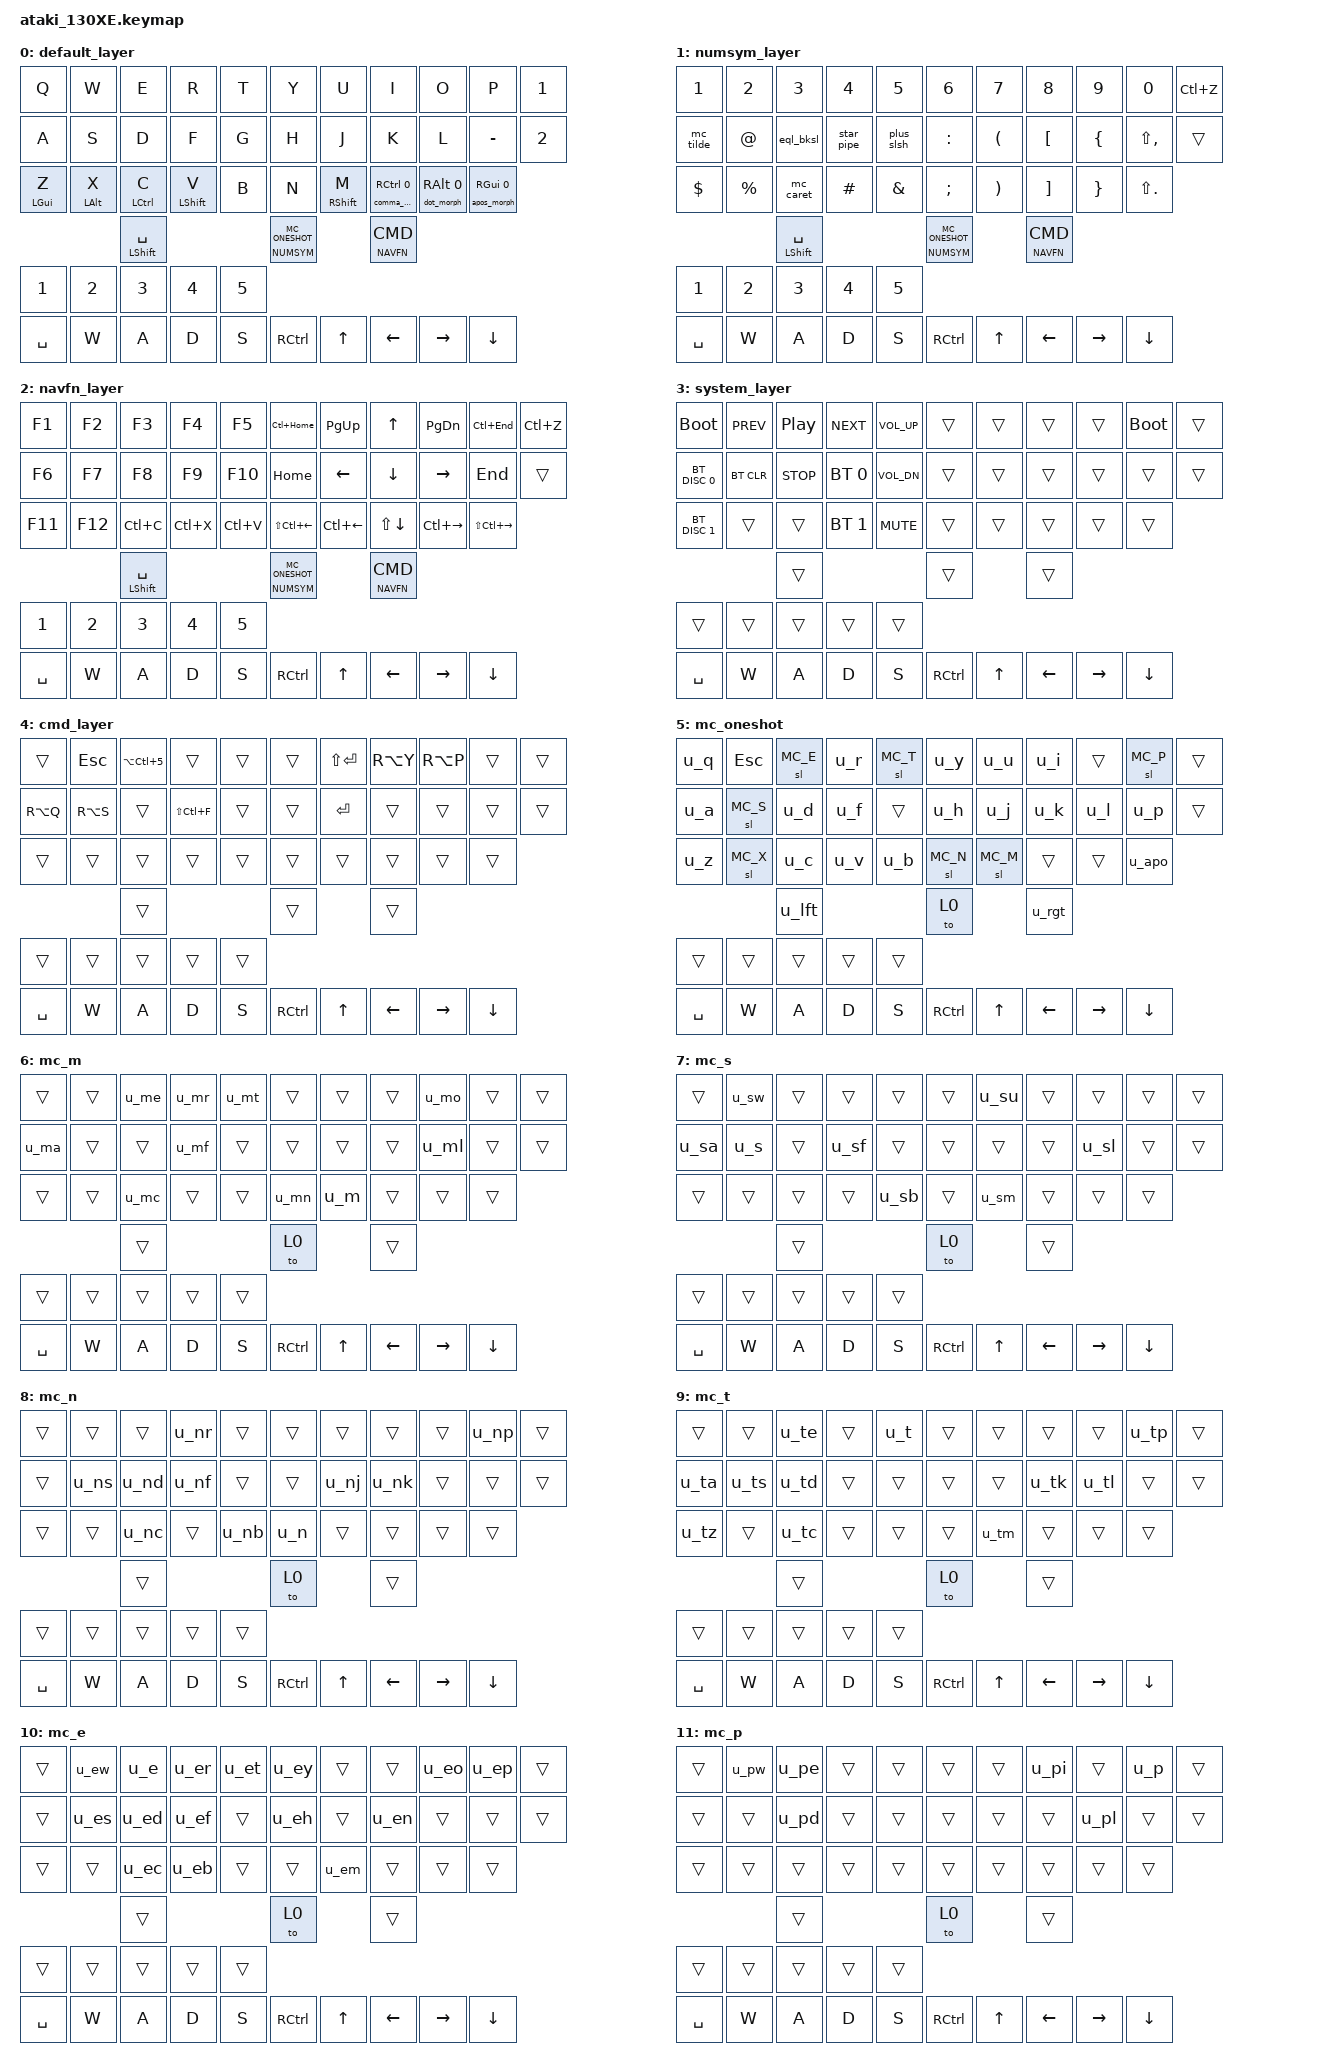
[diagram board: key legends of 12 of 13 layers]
#include <behaviors.dtsi>
#include <dt-bindings/zmk/keys.h>
#include <dt-bindings/zmk/bt.h>
#include "../../../inc/helpers.h"

// Layers
#define BASE 0
#define NUMSYM 1
#define NAVFN 2
#define SYSTEM 3
#define CMD 4
#define BASE_LAYERS BASE

#define MC_ONESHOT 5
#define MC_M       6
#define MC_S       7
#define MC_N       8
#define MC_T       9
#define MC_E       10
#define MC_P       11
#define MC_X       12

#define toM &sl MC_M
#define toS &sl MC_S
#define toN &sl MC_N
#define toT &sl MC_T
#define toE &sl MC_E
#define toP &sl MC_P
#define toX &sl MC_X

#define ___ &trans

/* How quickly Combo keys must be pressed together */
#define COMBO_TIMEOUT_MS 30
/* Macro timers; can be increased for systems that don't like 0ms Macros */
#define FAST_MACRO_TAP_MS 0
#define FAST_MACRO_WAIT_MS 0

/* Custom base layer punctuation */
SHIFT_MORPH(comma_qust, &kp COMMA, &kp QMARK)
SHIFT_MORPH(dot_exc, &kp DOT, &kp EXCL)
SHIFT_MORPH(eql_bksl, &kp EQUAL, &kp BSLH)
SHIFT_MORPH(star_pipe, &kp STAR, &kp PIPE)
SHIFT_MORPH(plus_slsh, &kp PLUS, &kp FSLH)

MY_HOLD_TAP(dot_morph, &dot_exc, &kp)
MY_HOLD_TAP(comma_morph, &comma_qust, &kp)
MY_HOLD_TAP(apos_morph, &mc_apos, &kp)

/ {
    behaviors {
       ht: hold_tap {
            compatible = "zmk,behavior-hold-tap";
            #binding-cells = <2>;
            flavor = "balanced";
            tapping-term-ms = <300>;
            require-prior-idle-ms = <100>;
            bindings = <&kp>, <&kp>;
        };

        /* Let Caps Word continue when typing Underscore */
        caps_word {
            continue-list = <UNDERSCORE MINUS BACKSPACE DELETE>;
        };

        hm: hold_mod {
            compatible = "zmk,behavior-hold-tap";
            #binding-cells = <2>;
            flavor = "balanced";
            tapping-term-ms = <300>;
            bindings = <&mo>, <&sl>;
        };
    };
    
    conditional_layers {
        compatible = "zmk,conditional-layers";
        tri_layer {
            if-layers = <NUMSYM NAVFN>;
            then-layer = <SYSTEM>;
        };
    };

#include "inc/leader_macros.h" 
#include "inc/combos.h" 
    
 // cheat-sheet for indexes
 //                   ───────────────
 //                  /35/36/37/38/39/
 // ┌───┬──┬──┬──┬──┬──┬──┬──┬──┬──┬────┐ ┌────────┐ ┌────────┐
 // │0  │1 │2 │3 │4 │5 │6 │7 │8 │9 │ 10 │ │      40│ │      45│
 // ├───┴┬─┴┬─┴┬─┴┬─┴┬─┴┬─┴┬─┴┬─┴┬─┴┬───┤ │   41   │ │   46   │
 // │11  │12│13│14│15│16│17│18│19│20│21 │ │42    43│ │47    48│
 // ├────┴─┬┴─┬┴─┬┴─┬┴─┬┴─┬┴─┬┴─┬┴──┴┬──┤ │   44   │ │   49   │
 // │22    │23│24│25│26│27│28│29│ 30 │31│ └────────┘ └────────┘
 // └─────┬┴──┴──┴──┴┬─┴┬─┴──┴──┴─┬──┴──┘  joystick1  joystick2
 //       │     32   │33│    34   │
 //       └──────────┴──┴─────────┘
/*
 * combos (see inc/combos.h for implementation)
 *                                  ───────────────────────────────────
 *                                 /      /      /      /      /      /
 *                                /      /      /      /      /      /
 * ┌──────┬─────┬─────┬─────┬─────┬─────┬─────┬─────┬─────┬─────┬──────────┐ ┌───────────┐ ┌───────────┐
 * │      │ +=Del=+=SftTab+ │     │     │     │ +=Del=+   │     │          │ │       ___ │ │       ___ │
 * │      │     │     │     │     │     │     │     │     │     │          │ │      /Spc\│ │      /Ctl\│
 * ├──────┴┬────┴┬────┴┬────┴┬────┴┬────┴┬────┴┬────┴┬────┴┬────┴┬─────────┤ │     W\___/│ │     ↑\___/│
 * │       │ +=BkSp=+=Tab=+  │     │     │     │  +=BkSp=+ │     │         │ │   ┌───┐   │ │   ┌───┐   │
 * │       │     │     │     │     │     │     │     │     │     │         │ │ A │J 1│ D │ │ ← │J 2│ → │
 * ├───────┴─┬───┴─┬───┴─┬───┴─┬───┴─┬───┴─┬───┴─┬───┴─┬───┴─┬───┴───┬─────┤ │   └───┘   │ │   └───┘   │
 * │    +=CtrlX+=CtrlC+CtrlV=+ │     │     │     │     │     │       │     │ │     S     │ │     ↓     │
 * │         │     │     │     │     │     │     │     │     │       │     │ └───────────┘ └───────────┘
 * └─────────┴┬────┴─────┴─────┴─┬───┴─┬───┴─────┴─────┴──┬──┴───────┴─────┘
 *            │                  │+=system==+             │
 *            │                  │     │                  │
 *            └──────────────────┴─────┴──────────────────┘
 */
    keymap {
        compatible = "zmk,keymap";
/*
 *                                  ───────────────────────────────────
 *                                 /      /      /      /      /      /
 *                                /      /      /      /      /      /
 * ┌──────┬─────┬─────┬─────┬─────┬─────┬─────┬─────┬─────┬─────┬──────────┐
 * │q     │w    │e    │r    │t    │y    │u    │i    │o    │p    │CtrlZ     │
 * │      │     │     │     │     │     │     │     │     │     │          │
 * ├──────┴┬────┴┬────┴┬────┴┬────┴┬────┴┬────┴┬────┴┬────┴┬────┴┬─────────┤
 * │a      │s    │d    │f    │g    │h    │j    │k    │l    │- _  │         │
 * │       │     │     │     │     │     │     │     │     │     │         │
 * ├───────┴─┬───┴─┬───┴─┬───┴─┬───┴─┬───┴─┬───┴─┬───┴─┬───┴─┬───┴───┬─────┤
 * │z        │x    │c    │v    │b    │n    │m    │, ?  │. !  │' "    │     │
 * │lgui     │lalt │lctl │lshft│     │     │rshft│rctl │ralt │rgui   │     │
 * └─────────┴┬────┴─────┴─────┴─┬───┴─┬───┴─────┴─────┴──┬──┴───────┴─────┘
 *            │      space       │lead │        cmd       │
 *            │      shift       │numsy│        navfn     │
 *            └──────────────────┴─────┴──────────────────┘
 */
        default_layer {
            bindings = <
            &kp Q      &kp W      &kp E      &kp R           &kp T           &kp Y                 &kp U         &kp I               &kp O             &kp P              &kp N1
            &kp A      &kp S      &kp D      &kp F           &kp G           &kp H                 &kp J         &kp K               &kp L             &kp MINUS          &kp N2
            &ht LGUI Z &ht LALT X &ht LCTL C &ht LSHFT V     &kp B           &kp N                 &ht RSHFT M   &comma_morph RCTL 0 &dot_morph RALT 0 &apos_morph RGUI 0
                                     &mt LSHFT SPACE                     &hm NUMSYM MC_ONESHOT                   &hm NAVFN CMD
            &kp N1  &kp N2  &kp N3  &kp N4  &kp N5
            &kp SPACE &kp W &kp A &kp D &kp S           &kp RCTL &kp UP &kp LEFT &kp RIGHT &kp DOWN
            >;
        };

/*
 *                                  ───────────────────────────────────
 *                                 /      /      /      /      /      /
 *                                /      /      /      /      /      /
 * ┌──────┬─────┬─────┬─────┬─────┬─────┬─────┬─────┬─────┬─────┬──────────┐
 * │1     │2    │3    │4    │5    │6    │7    │8    │9    │0    │CtrlZ     │
 * │      │     │     │     │     │     │     │     │     │     │          │
 * ├──────┴┬────┴┬────┴┬────┴┬────┴┬────┴┬────┴┬────┴┬────┴┬────┴┬─────────┤
 * │~      │@    │= \  │* |  │+ /  │:    │(    │[    │{    │<    │         │
 * │       │     │     │     │     │     │     │     │     │     │         │
 * ├───────┴─┬───┴─┬───┴─┬───┴─┬───┴─┬───┴─┬───┴─┬───┴─┬───┴─┬───┴───┬─────┤
 * │$        │%    │^    │#    │&    │;    │)    │] ,  │} .  │>      │     │
 * │         │     │     │     │     │     │     │     │     │       │     │
 * └─────────┴┬────┴─────┴─────┴─┬───┴─┬───┴─────┴─────┴──┬──┴───────┴─────┘
 *            │      space       │lead │        cmd       │
 *            │      shift       │numsy│        navfn     │
 *            └──────────────────┴─────┴──────────────────┘
 */
        numsym_layer {
            bindings = <
            &kp N1     &kp N2    &kp N3    &kp N4          &kp N5          &kp N6                &kp N7        &kp N8        &kp N9   &kp N0        &kp LC(Z)
            &mc_tilde  &kp AT    &eql_bksl &star_pipe      &plus_slsh      &kp COLON             &kp LPAR      &kp LBKT      &kp LBRC &kp LS(COMMA) ___    
            &kp DOLLAR &kp PRCNT &mc_caret &kp HASH        &kp AMPS        &kp SEMI              &kp RPAR      &kp RBKT      &kp RBRC &kp LS(DOT) 
                                     &mt LSHFT SPACE                     &hm NUMSYM MC_ONESHOT                   &hm NAVFN CMD
            &kp N1  &kp N2  &kp N3  &kp N4  &kp N5
            &kp SPACE &kp W &kp A &kp D &kp S           &kp RCTL &kp UP &kp LEFT &kp RIGHT &kp DOWN
            >;
        };

/*
 *                                  ───────────────────────────────────
 *                                 /      /      /      /      /      /
 *                                /      /      /      /      /      /
 * ┌──────┬─────┬─────┬─────┬─────┬─────┬─────┬─────┬─────┬─────┬──────────┐
 * │F1    │F2   │F3   │F4   │F5   │Top  │PgUp │↑    │PgDwn│Bottm│CtrlZ     │
 * │      │     │     │     │     │     │     │     │     │     │          │
 * ├──────┴┬────┴┬────┴┬────┴┬────┴┬────┴┬────┴┬────┴┬────┴┬────┴┬─────────┤
 * │F6     │F7   │F8   │F9   │F10  │Home │←    │↓    │→    │End  │         │
 * │       │     │     │     │     │     │     │     │     │     │         │
 * ├───────┴─┬───┴─┬───┴─┬───┴─┬───┴─┬───┴─┬───┴─┬───┴─┬───┴─┬───┴───┬─────┤
 * │F11      │F12  │CtrlC│CtrlX│CtrlV│SelWL│WrdLf│SelLn│WrdRg│SelWR  │     │
 * │         │     │     │     │     │     │     │     │     │       │     │
 * └─────────┴┬────┴─────┴─────┴─┬───┴─┬───┴─────┴─────┴──┬──┴───────┴─────┘
 *            │      space       │lead │        cmd       │
 *            │      shift       │numsy│        navfn     │
 *            └──────────────────┴─────┴──────────────────┘
 */
        navfn_layer {
            bindings = <
            &kp F1    &kp F2    &kp F3    &kp F4          &kp F5          &kp LC(HOME)          &kp PG_UP     &kp UP        &kp PG_DN     &kp LC(END)       &kp LC(Z)
            &kp F6    &kp F7    &kp F8    &kp F9          &kp F10         &kp HOME              &kp LEFT      &kp DOWN      &kp RIGHT     &kp END           ___
            &kp F11   &kp F12   &kp LC(C) &kp LC(X)       &kp LC(V)       &kp LS(LC(LEFT))      &kp LC(LEFT)  &kp LS(DOWN)  &kp LC(RIGHT) &kp LS(LC(RIGHT))
                                     &mt LSHFT SPACE                     &hm NUMSYM MC_ONESHOT                   &hm NAVFN CMD
            &kp N1  &kp N2  &kp N3  &kp N4  &kp N5
            &kp SPACE &kp W &kp A &kp D &kp S           &kp RCTL &kp UP &kp LEFT &kp RIGHT &kp DOWN
            >;
        };

/*
 *                                  ───────────────────────────────────
 *                                 /      /      /      /      /      /
 *                                /      /      /      /      /      /
 * ┌──────┬─────┬─────┬─────┬─────┬─────┬─────┬─────┬─────┬─────┬──────────┐
 * │Boot  │track│play │track│vol  │     │     │     │     │     │          │
 * │      │prev │pause│next │up   │     │     │     │     │     │          │
 * ├──────┴┬────┴┬────┴┬────┴┬────┴┬────┴┬────┴┬────┴┬────┴┬────┴┬─────────┤
 * │BT     │BT   │stop │BT   │vol  │     │     │     │     │     │         │
 * │Discn.0│Clear│     │Sel.0│down │     │     │     │     │     │         │
 * ├───────┴─┬───┴─┬───┴─┬───┴─┬───┴─┬───┴─┬───┴─┬───┴─┬───┴─┬───┴───┬─────┤
 * │BT       │     │     │BT   │vol  │     │     │     │     │       │     │
 * │Discn.1  │     │     │Sel.1│mute │     │     │     │     │       │     │
 * └─────────┴┬────┴─────┴─────┴─┬───┴─┬───┴─────┴─────┴──┬──┴───────┴─────┘
 *            │      space       │lead │        cmd       │
 *            │      shift       │numsy│        navfn     │
 *            └──────────────────┴─────┴──────────────────┘
 */
        system_layer {
            bindings = <
            &bootloader   &kp C_PREV &kp C_PP   &kp C_NEXT   &kp C_VOL_UP ___ ___ ___ ___ &bootloader ___   
            &bt BT_DISC 0 &bt BT_CLR &kp C_STOP &bt BT_SEL 0 &kp C_VOL_DN ___ ___ ___ ___ ___         ___
            &bt BT_DISC 1 ___        ___        &bt BT_SEL 1 &kp C_MUTE   ___ ___ ___ ___ ___      
                                    ___       ___        ___
            ___ ___ ___ ___ ___
            &kp SPACE &kp W &kp A &kp D &kp S           &kp RCTL &kp UP &kp LEFT &kp RIGHT &kp DOWN
            >;
        };

/*
 *                                  ───────────────────────────────────
 *                                 /      /      /      /      /      /
 *                                /      /      /      /      /      /
 * ┌──────┬─────┬─────┬─────┬─────┬─────┬─────┬─────┬─────┬─────┬──────────┐
 * │      │Esc  │€    │     │     │     │Sft+ │ü    │ö    │     │          │
 * │      │     │     │     │     │     │Retrn│     │     │     │          │
 * ├──────┴┬────┴┬────┴┬────┴┬────┴┬────┴┬────┴┬────┴┬────┴┬────┴┬─────────┤
 * │ä      │ß    │     │Ctrl │     │     │Retrn│     │     │     │         │
 * │       │     │     │Sft F│     │     │     │     │     │     │         │
 * ├───────┴─┬───┴─┬───┴─┬───┴─┬───┴─┬───┴─┬───┴─┬───┴─┬───┴─┬───┴───┬─────┤
 * │         │     │     │     │     │     │     │     │     │       │     │
 * │         │     │     │     │     │     │     │     │     │       │     │
 * └─────────┴┬────┴─────┴─────┴─┬───┴─┬───┴─────┴─────┴──┬──┴───────┴─────┘
 *            │      space       │lead │        cmd       │
 *            │      shift       │numsy│        navfn     │
 *            └──────────────────┴─────┴──────────────────┘
 */
        cmd_layer {
            bindings = <
            ___       &kp ESC   &kp LA(LC(N5)) ___           ___ ___ &kp LS(RET) &kp RA(Y) &kp RA(P) ___ ___  
            &kp RA(Q) &kp RA(S) ___            &kp LS(LC(F)) ___ ___ &kp RET     ___       ___       ___ ___
            ___       ___       ___            ___           ___ ___ ___         ___       ___       ___ 
                                    ___       ___        ___
            ___ ___ ___ ___ ___
            &kp SPACE &kp W &kp A &kp D &kp S           &kp RCTL &kp UP &kp LEFT &kp RIGHT &kp DOWN
            >;
        };

        mc_oneshot {
            bindings = <
            &u_q  &kp ESC toE   &u_r  toT     &u_y  &u_u  &u_i  ___   toP    ___
            &u_a  toS     &u_d  &u_f  ___     &u_h  &u_j  &u_k  &u_l  &u_p   ___
            &u_z  toX     &u_c  &u_v  &u_b    toN   toM   ___   ___   &u_apo 
                          &u_lft     &to 0      &u_rgt
            ___ ___ ___ ___ ___
            &kp SPACE &kp W &kp A &kp D &kp S           &kp RCTL &kp UP &kp LEFT &kp RIGHT &kp DOWN
            >;
        };

        // Mongo commands (f,l,a,r,t,n,e,o,c + self-reference m)
        mc_m {
            bindings = <
            ___   ___   &u_me  &u_mr  &u_mt   ___   ___   ___   &u_mo  ___   ___
            &u_ma ___   ___    &u_mf  ___     ___   ___   ___   &u_ml  ___   ___
            ___   ___   &u_mc  ___    ___     &u_mn &u_m  ___   ___    ___  
                          ___        &to 0      ___
            ___ ___ ___ ___ ___
            &kp SPACE &kp W &kp A &kp D &kp S           &kp RCTL &kp UP &kp LEFT &kp RIGHT &kp DOWN
            >;
        };

        // Status messages (w,f,b,l,u,a,m + self-reference s)
        mc_s {
            bindings = <
            ___   &u_sw ___   ___    ___     ___   &u_su ___   ___   ___   ___
            &u_sa &u_s  ___   &u_sf  ___     ___   ___   ___   &u_sl ___   ___
            ___   ___   ___   ___    &u_sb   ___   &u_sm ___   ___   ___   
                          ___        &to 0      ___
            ___ ___ ___ ___ ___
            &kp SPACE &kp W &kp A &kp D &kp S           &kp RCTL &kp UP &kp LEFT &kp RIGHT &kp DOWN
            >;
        };

        // Namen (f,p,b,j,r,s,c,d,k + self-reference n)
        mc_n {
            bindings = <
            ___   ___   ___   &u_nr  ___     ___   ___   ___   ___   &u_np ___
            ___   &u_ns &u_nd &u_nf  ___     ___   &u_nj &u_nk ___   ___   ___
            ___   ___   &u_nc ___    &u_nb   &u_n  ___   ___   ___   ___  
                          ___        &to 0      ___
            ___ ___ ___ ___ ___
            &kp SPACE &kp W &kp A &kp D &kp S           &kp RCTL &kp UP &kp LEFT &kp RIGHT &kp DOWN
            >;
        };

        // Text-Snippets (p,l,a,s,m,e,z,c,d,k + self-reference t)
        mc_t {
            bindings = <
            ___   ___   &u_te ___    &u_t    ___   ___   ___   ___   &u_tp ___
            &u_ta &u_ts &u_td ___    ___     ___   ___   &u_tk &u_tl ___   ___
            &u_tz ___   &u_tc ___    ___     ___   &u_tm ___   ___   ___  
                          ___        &to 0      ___
            ___ ___ ___ ___ ___
            &kp SPACE &kp W &kp A &kp D &kp S           &kp RCTL &kp UP &kp LEFT &kp RIGHT &kp DOWN
            >;
        };

        // Emojis (w,f,p,y,r,s,t,m,o,c,d,v,k,h + self-reference e)
        mc_e {
            bindings = <
            ___   &u_ew &u_e  &u_er  &u_et   &u_ey ___   ___   &u_eo &u_ep ___
            ___   &u_es &u_ed &u_ef  ___     &u_eh ___   &u_en ___   ___   ___
            ___   ___   &u_ec &u_eb  ___     ___   &u_em ___   ___   ___ 
                          ___        &to 0      ___
            ___ ___ ___ ___ ___
            &kp SPACE &kp W &kp A &kp D &kp S           &kp RCTL &kp UP &kp LEFT &kp RIGHT &kp DOWN
            >;
        };

        // Code-Snippets (w,l,e,i,d + self-reference p)
        mc_p {
            bindings = <
            ___   &u_pw &u_pe ___    ___     ___   ___   &u_pi ___   &u_p  ___
            ___   ___   &u_pd ___    ___     ___   ___   ___   &u_pl ___   ___
            ___   ___   ___   ___    ___     ___   ___   ___   ___   ___  
                          ___        &to 0      ___
            ___ ___ ___ ___ ___
            &kp SPACE &kp W &kp A &kp D &kp S           &kp RCTL &kp UP &kp LEFT &kp RIGHT &kp DOWN
            >;
        };

        // Programme starten (w,f,p,a,m,n,e,o + self-reference x)
        mc_x {
            bindings = <
            ___   &u_xw &u_xe ___    ___     ___   ___   ___   &u_xo &u_xp ___
            &u_xa ___   ___   &u_xf  ___     ___   ___   ___   ___   ___   ___
            ___   &u_xx &u_xc ___    ___     &u_xn &u_xm ___   ___   ___ 
                          ___        &to 0      ___
            ___ ___ ___ ___ ___
            &kp SPACE &kp W &kp A &kp D &kp S           &kp RCTL &kp UP &kp LEFT &kp RIGHT &kp DOWN
            >;
        };
    };
/*
 * leader one-key (see inc/leader_macros.h for implementation)
 *                                  ───────────────────────────────────
 *                                 /      /      /      /      /      /
 *                                /      /      /      /      /      /
 * ┌──────┬─────┬─────┬─────┬─────┬─────┬─────┬─────┬─────┬─────┬──────────┐
 * │Lock  │     │Doubl│Comnt│Multi│MltCm│Multi│Dupli│     │     │          │
 * │      │     │Shift│     │Comnt│InteJ│Code │Line │     │     │          │
 * ├──────┴┬────┴┬────┴┬────┴┬────┴┬────┴┬────┴┬────┴┬────┴┬────┴┬─────────┤
 * │->     │WinR │PrtSc│Mute/│     │- [ ]│()   │[]   │{}   │´´   │         │
 * │       │     │     │Unmte│     │     │     │     │     │     │         │
 * ├───────┴─┬───┴─┬───┴─┬───┴─┬───┴─┬───┴─┬───┴─┬───┴─┬───┴─┬───┴───┬─────┤
 * │CtrlZ    │CtrlY│CtrlC│CtrlX│CtrlV│Alt  │Shift│     │     │""     │     │
 * │         │     │     │     │     │CtrlV│CtrlV│     │     │       │     │
 * └─────────┴┬────┴─────┴─────┴─┬───┴─┬───┴─────┴─────┴──┬──┴───────┴─────┘
 *            │      WinLf       │/lead│        WinRg     │
 *            │                  │     │                  │
 *            └──────────────────┴─────┴──────────────────┘
 */
};
